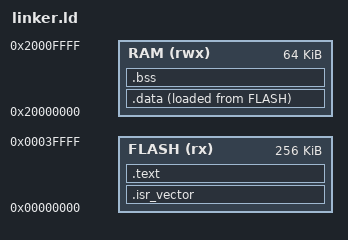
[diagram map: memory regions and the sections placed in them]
MEMORY
{
    FLASH (rx) : ORIGIN = 0x00000000, LENGTH = 256K
    RAM (rwx)  : ORIGIN = 0x20000000, LENGTH = 64K
}

ENTRY(Reset_Handler)

SECTIONS
{
    .isr_vector :
    {
        KEEP(*(.isr_vector))
    } > FLASH

    .text :
    {
        *(.text*)
        *(.rodata*)
        . = ALIGN(4);
    } > FLASH

    .data :
    {
        _sdata = .;
        *(.data*)
        . = ALIGN(4);
        _edata = .;
    } > RAM AT > FLASH

    .bss :
    {
        _sbss = .;
        *(.bss*)
        *(COMMON)
        . = ALIGN(4);
        _ebss = .;
    } > RAM

    . = ALIGN(8);
    _end = .;
    
    PROVIDE(end = .);
    PROVIDE(_heap_start = .);
}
